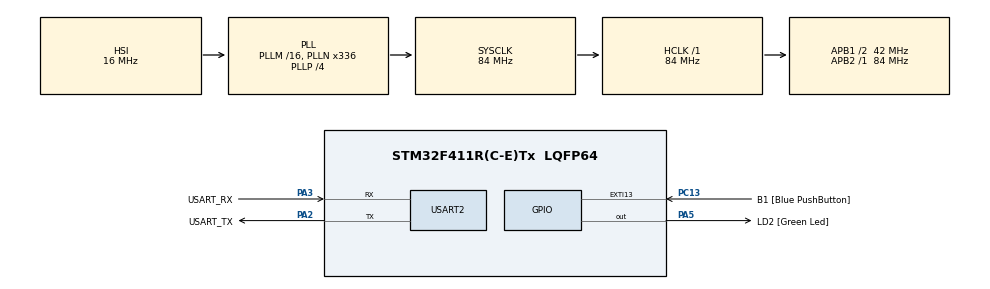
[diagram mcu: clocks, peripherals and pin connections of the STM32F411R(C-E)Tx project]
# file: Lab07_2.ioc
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Dma.MEMTOMEM.2.Direction=DMA_MEMORY_TO_MEMORY
Dma.MEMTOMEM.2.FIFOMode=DMA_FIFOMODE_ENABLE
Dma.MEMTOMEM.2.FIFOThreshold=DMA_FIFO_THRESHOLD_FULL
Dma.MEMTOMEM.2.Instance=DMA2_Stream0
Dma.MEMTOMEM.2.MemBurst=DMA_MBURST_SINGLE
Dma.MEMTOMEM.2.MemDataAlignment=DMA_MDATAALIGN_BYTE
Dma.MEMTOMEM.2.MemInc=DMA_MINC_ENABLE
Dma.MEMTOMEM.2.Mode=DMA_NORMAL
Dma.MEMTOMEM.2.PeriphBurst=DMA_PBURST_SINGLE
Dma.MEMTOMEM.2.PeriphDataAlignment=DMA_PDATAALIGN_BYTE
Dma.MEMTOMEM.2.PeriphInc=DMA_PINC_ENABLE
Dma.MEMTOMEM.2.Priority=DMA_PRIORITY_LOW
Dma.Request0=USART2_RX
Dma.Request1=USART2_TX
Dma.Request2=MEMTOMEM
Dma.USART2_RX.0.Direction=DMA_PERIPH_TO_MEMORY
Dma.USART2_RX.0.FIFOMode=DMA_FIFOMODE_DISABLE
Dma.USART2_RX.0.Instance=DMA1_Stream5
Dma.USART2_RX.0.MemDataAlignment=DMA_MDATAALIGN_BYTE
Dma.USART2_RX.0.MemInc=DMA_MINC_ENABLE
Dma.USART2_RX.0.Mode=DMA_CIRCULAR
Dma.USART2_RX.0.PeriphDataAlignment=DMA_PDATAALIGN_BYTE
Dma.USART2_RX.0.PeriphInc=DMA_PINC_DISABLE
Dma.USART2_RX.0.Priority=DMA_PRIORITY_LOW
Dma.USART2_TX.1.Direction=DMA_MEMORY_TO_PERIPH
Dma.USART2_TX.1.FIFOMode=DMA_FIFOMODE_DISABLE
Dma.USART2_TX.1.Instance=DMA1_Stream6
Dma.USART2_TX.1.MemDataAlignment=DMA_MDATAALIGN_BYTE
Dma.USART2_TX.1.MemInc=DMA_MINC_ENABLE
Dma.USART2_TX.1.Mode=DMA_NORMAL
Dma.USART2_TX.1.PeriphDataAlignment=DMA_PDATAALIGN_BYTE
Dma.USART2_TX.1.PeriphInc=DMA_PINC_DISABLE
Dma.USART2_TX.1.Priority=DMA_PRIORITY_LOW
Mcu.Family=STM32F4
Mcu.Name=STM32F411R(C-E)Tx
Mcu.Package=LQFP64
NVIC.DMA1_Stream5_IRQn=true\:0\:0\:false\:false\:true\:false\:true\:true
NVIC.DMA1_Stream6_IRQn=true\:0\:0\:false\:false\:true\:false\:true\:true
NVIC.PriorityGroup=NVIC_PRIORITYGROUP_0
NVIC.USART2_IRQn=true\:0\:0\:false\:false\:true\:true\:true\:true
PA13.GPIO_Label=TMS
PA13.Mode=Serial_Wire
PA13.Signal=SYS_JTMS-SWDIO
PA14.GPIO_Label=TCK
PA14.Mode=Serial_Wire
PA14.Signal=SYS_JTCK-SWCLK
PA2.GPIO_Label=USART_TX
PA2.Mode=Asynchronous
PA2.Signal=USART2_TX
PA3.GPIO_Label=USART_RX
PA3.Mode=Asynchronous
PA3.Signal=USART2_RX
PA5.GPIO_Label=LD2 [Green Led]
PA5.Signal=GPIO_Output
PB3.GPIO_Label=SWO
PB3.Signal=SYS_JTDO-SWO
PC13-ANTI_TAMP.GPIO_Label=B1 [Blue PushButton]
PC13-ANTI_TAMP.GPIO_ModeDefaultEXTI=GPIO_MODE_IT_FALLING
PC13-ANTI_TAMP.Signal=GPXTI13
PC14-OSC32_IN.Mode=LSE-External-Oscillator
PC14-OSC32_IN.Signal=RCC_OSC32_IN
PC15-OSC32_OUT.Mode=LSE-External-Oscillator
PC15-OSC32_OUT.Signal=RCC_OSC32_OUT
PH0\ -\ OSC_IN.Mode=HSE-External-Clock-Source
PH0\ -\ OSC_IN.Signal=RCC_OSC_IN
PH1\ -\ OSC_OUT.Mode=HSE-External-Clock-Source
PH1\ -\ OSC_OUT.Signal=RCC_OSC_OUT
ProjectManager.HeapSize=0x200
ProjectManager.StackSize=0x400
ProjectManager.TargetToolchain=STM32CubeIDE
RCC.48MHZClocksFreq_Value=84000000
RCC.AHBFreq_Value=84000000
RCC.APB1CLKDivider=RCC_HCLK_DIV2
RCC.APB1Freq_Value=42000000
RCC.APB1TimFreq_Value=84000000
RCC.APB2Freq_Value=84000000
RCC.APB2TimFreq_Value=84000000
RCC.CortexFreq_Value=84000000
RCC.FLatency-AdvancedSettings=FLASH_LATENCY_2
RCC.HCLKFreq_Value=84000000
RCC.HSE_VALUE=8000000
RCC.HSI_VALUE=16000000
RCC.PLLN=336
RCC.PLLP=RCC_PLLP_DIV4
RCC.SYSCLKFreq_VALUE=84000000
RCC.SYSCLKSource=RCC_SYSCLKSOURCE_PLLCLK
RCC.VCOOutputFreq_Value=336000000
USART2.VirtualMode=VM_ASYNC
board=NUCLEO-F411RE

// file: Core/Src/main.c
/* USER CODE BEGIN Header */
/**
  ******************************************************************************
  * @file           : main.c
  * @brief          : Main program body
  ******************************************************************************
  * @attention
  *
  * Copyright (c) 2023 STMicroelectronics.
  * All rights reserved.
  *
  * This software is licensed under terms that can be found in the LICENSE file
  * in the root directory of this software component.
  * If no LICENSE file comes with this software, it is provided AS-IS.
  *
  ******************************************************************************
  */
/* USER CODE END Header */
#include "main.h"

UART_HandleTypeDef huart2;
DMA_HandleTypeDef hdma_usart2_rx;
DMA_HandleTypeDef hdma_usart2_tx;

DMA_HandleTypeDef hdma_memtomem_dma2_stream0;

void SystemClock_Config(void);
static void MX_GPIO_Init(void);
static void MX_DMA_Init(void);
static void MX_USART2_UART_Init(void);

/* USER CODE BEGIN 0 */
char buffer[512];
/* USER CODE END 0 */

int main(void)
{

  /* MCU Configuration--------------------------------------------------------*/

  /* Reset of all peripherals, Initializes the Flash interface and the Systick. */
  HAL_Init();

  /* Configure the system clock */
  SystemClock_Config();

  /* Initialize all configured peripherals */
  MX_GPIO_Init();
  MX_DMA_Init();
  MX_USART2_UART_Init();

  /* Infinite loop */
  while (1)
  {

    /* USER CODE BEGIN 3 */
	  HAL_GPIO_TogglePin(GPIOA, GPIO_PIN_5);
	  HAL_UART_Receive_DMA(&huart2, buffer, 512);

	  HAL_Delay(200);
  }
  /* USER CODE END 3 */
}

void SystemClock_Config(void)
{
  RCC_OscInitTypeDef RCC_OscInitStruct = {0};
  RCC_ClkInitTypeDef RCC_ClkInitStruct = {0};

  /** Configure the main internal regulator output voltage
  */
  __HAL_RCC_PWR_CLK_ENABLE();
  __HAL_PWR_VOLTAGESCALING_CONFIG(PWR_REGULATOR_VOLTAGE_SCALE1);

  /** Initializes the RCC Oscillators according to the specified parameters
  * in the RCC_OscInitTypeDef structure.
  */
  RCC_OscInitStruct.OscillatorType = RCC_OSCILLATORTYPE_HSI;
  RCC_OscInitStruct.HSIState = RCC_HSI_ON;
  RCC_OscInitStruct.HSICalibrationValue = RCC_HSICALIBRATION_DEFAULT;
  RCC_OscInitStruct.PLL.PLLState = RCC_PLL_ON;
  RCC_OscInitStruct.PLL.PLLSource = RCC_PLLSOURCE_HSI;
  RCC_OscInitStruct.PLL.PLLM = 16;
  RCC_OscInitStruct.PLL.PLLN = 336;
  RCC_OscInitStruct.PLL.PLLP = RCC_PLLP_DIV4;
  RCC_OscInitStruct.PLL.PLLQ = 4;
  if (HAL_RCC_OscConfig(&RCC_OscInitStruct) != HAL_OK)
  {
    Error_Handler();
  }

  /** Initializes the CPU, AHB and APB buses clocks
  */
  RCC_ClkInitStruct.ClockType = RCC_CLOCKTYPE_HCLK|RCC_CLOCKTYPE_SYSCLK
                              |RCC_CLOCKTYPE_PCLK1|RCC_CLOCKTYPE_PCLK2;
  RCC_ClkInitStruct.SYSCLKSource = RCC_SYSCLKSOURCE_PLLCLK;
  RCC_ClkInitStruct.AHBCLKDivider = RCC_SYSCLK_DIV1;
  RCC_ClkInitStruct.APB1CLKDivider = RCC_HCLK_DIV2;
  RCC_ClkInitStruct.APB2CLKDivider = RCC_HCLK_DIV1;

  if (HAL_RCC_ClockConfig(&RCC_ClkInitStruct, FLASH_LATENCY_2) != HAL_OK)
  {
    Error_Handler();
  }
}

static void MX_USART2_UART_Init(void)
{

  huart2.Instance = USART2;
  huart2.Init.BaudRate = 115200;
  huart2.Init.WordLength = UART_WORDLENGTH_8B;
  huart2.Init.StopBits = UART_STOPBITS_1;
  huart2.Init.Parity = UART_PARITY_NONE;
  huart2.Init.Mode = UART_MODE_TX_RX;
  huart2.Init.HwFlowCtl = UART_HWCONTROL_NONE;
  huart2.Init.OverSampling = UART_OVERSAMPLING_16;
  if (HAL_UART_Init(&huart2) != HAL_OK)
  {
    Error_Handler();
  }

}

static void MX_DMA_Init(void)
{

  /* DMA controller clock enable */
  __HAL_RCC_DMA1_CLK_ENABLE();
  __HAL_RCC_DMA2_CLK_ENABLE();

  /* Configure DMA request hdma_memtomem_dma2_stream0 on DMA2_Stream0 */
  hdma_memtomem_dma2_stream0.Instance = DMA2_Stream0;
  hdma_memtomem_dma2_stream0.Init.Channel = DMA_CHANNEL_0;
  hdma_memtomem_dma2_stream0.Init.Direction = DMA_MEMORY_TO_MEMORY;
  hdma_memtomem_dma2_stream0.Init.PeriphInc = DMA_PINC_ENABLE;
  hdma_memtomem_dma2_stream0.Init.MemInc = DMA_MINC_ENABLE;
  hdma_memtomem_dma2_stream0.Init.PeriphDataAlignment = DMA_PDATAALIGN_BYTE;
  hdma_memtomem_dma2_stream0.Init.MemDataAlignment = DMA_MDATAALIGN_BYTE;
  hdma_memtomem_dma2_stream0.Init.Mode = DMA_NORMAL;
  hdma_memtomem_dma2_stream0.Init.Priority = DMA_PRIORITY_LOW;
  hdma_memtomem_dma2_stream0.Init.FIFOMode = DMA_FIFOMODE_ENABLE;
  hdma_memtomem_dma2_stream0.Init.FIFOThreshold = DMA_FIFO_THRESHOLD_FULL;
  hdma_memtomem_dma2_stream0.Init.MemBurst = DMA_MBURST_SINGLE;
  hdma_memtomem_dma2_stream0.Init.PeriphBurst = DMA_PBURST_SINGLE;
  if (HAL_DMA_Init(&hdma_memtomem_dma2_stream0) != HAL_OK)
  {
    Error_Handler( );
  }

  /* DMA interrupt init */
  /* DMA1_Stream5_IRQn interrupt configuration */
  HAL_NVIC_SetPriority(DMA1_Stream5_IRQn, 0, 0);
  HAL_NVIC_EnableIRQ(DMA1_Stream5_IRQn);
  /* DMA1_Stream6_IRQn interrupt configuration */
  HAL_NVIC_SetPriority(DMA1_Stream6_IRQn, 0, 0);
  HAL_NVIC_EnableIRQ(DMA1_Stream6_IRQn);

}

static void MX_GPIO_Init(void)
{
  GPIO_InitTypeDef GPIO_InitStruct = {0};

  /* GPIO Ports Clock Enable */
  __HAL_RCC_GPIOC_CLK_ENABLE();
  __HAL_RCC_GPIOH_CLK_ENABLE();
  __HAL_RCC_GPIOA_CLK_ENABLE();
  __HAL_RCC_GPIOB_CLK_ENABLE();

  /*Configure GPIO pin Output Level */
  HAL_GPIO_WritePin(LD2_GPIO_Port, LD2_Pin, GPIO_PIN_RESET);

  /*Configure GPIO pin : B1_Pin */
  GPIO_InitStruct.Pin = B1_Pin;
  GPIO_InitStruct.Mode = GPIO_MODE_IT_FALLING;
  GPIO_InitStruct.Pull = GPIO_NOPULL;
  HAL_GPIO_Init(B1_GPIO_Port, &GPIO_InitStruct);

  /*Configure GPIO pin : LD2_Pin */
  GPIO_InitStruct.Pin = LD2_Pin;
  GPIO_InitStruct.Mode = GPIO_MODE_OUTPUT_PP;
  GPIO_InitStruct.Pull = GPIO_NOPULL;
  GPIO_InitStruct.Speed = GPIO_SPEED_FREQ_LOW;
  HAL_GPIO_Init(LD2_GPIO_Port, &GPIO_InitStruct);

}

/* USER CODE BEGIN 4 */
void HAL_UART_RxHalfCpltCallback(UART_HandleTypeDef *huart)
{
	HAL_UART_Transmit_DMA(&huart2, buffer, 256);
}

void HAL_UART_RxCpltCallback(UART_HandleTypeDef *huart)
{
	HAL_UART_Transmit_DMA(&huart2, buffer+256, 256);
}
/* USER CODE END 4 */

void Error_Handler(void)
{
  __disable_irq();
  while (1)
  {
  }
}
